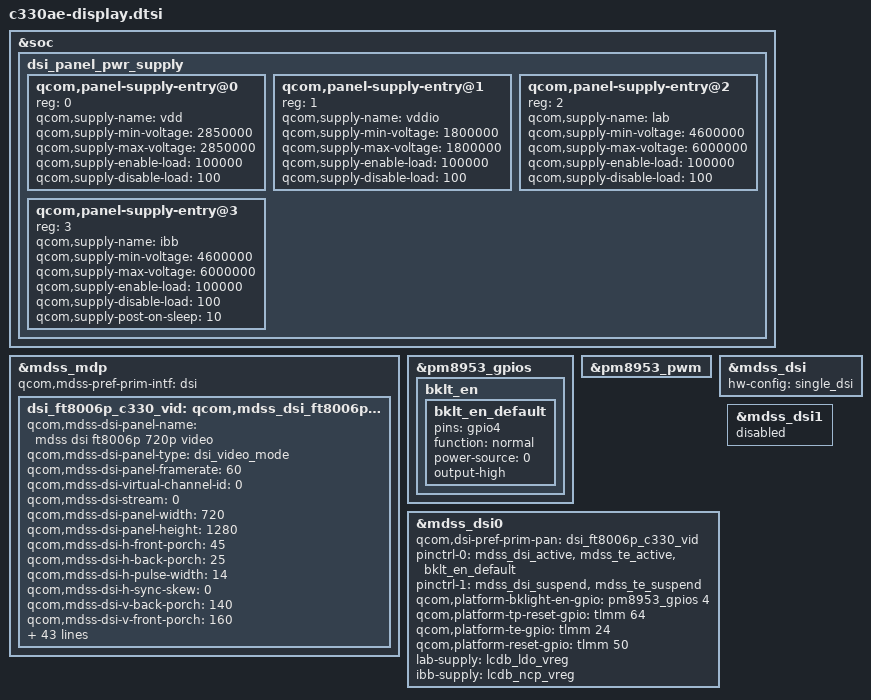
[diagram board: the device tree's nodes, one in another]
/* C330AE FT8006P 720p single-DSI panel. */

&soc {
	dsi_panel_pwr_supply: dsi_panel_pwr_supply {
		#address-cells = <1>;
		#size-cells = <0>;

		qcom,panel-supply-entry@0 {
			reg = <0>;
			qcom,supply-name = "vdd";
			qcom,supply-min-voltage = <2850000>;
			qcom,supply-max-voltage = <2850000>;
			qcom,supply-enable-load = <100000>;
			qcom,supply-disable-load = <100>;
		};

		qcom,panel-supply-entry@1 {
			reg = <1>;
			qcom,supply-name = "vddio";
			qcom,supply-min-voltage = <1800000>;
			qcom,supply-max-voltage = <1800000>;
			qcom,supply-enable-load = <100000>;
			qcom,supply-disable-load = <100>;
		};

		qcom,panel-supply-entry@2 {
			reg = <2>;
			qcom,supply-name = "lab";
			qcom,supply-min-voltage = <4600000>;
			qcom,supply-max-voltage = <6000000>;
			qcom,supply-enable-load = <100000>;
			qcom,supply-disable-load = <100>;
		};

		qcom,panel-supply-entry@3 {
			reg = <3>;
			qcom,supply-name = "ibb";
			qcom,supply-min-voltage = <4600000>;
			qcom,supply-max-voltage = <6000000>;
			qcom,supply-enable-load = <100000>;
			qcom,supply-disable-load = <100>;
			qcom,supply-post-on-sleep = <10>;
		};
	};
};

&mdss_mdp {
	qcom,mdss-pref-prim-intf = "dsi";

	dsi_ft8006p_c330_vid: qcom,mdss_dsi_ft8006p_720p_video {
		qcom,mdss-dsi-panel-name = "mdss dsi ft8006p 720p video";
		qcom,mdss-dsi-panel-type = "dsi_video_mode";
		qcom,mdss-dsi-panel-framerate = <60>;
		qcom,mdss-dsi-virtual-channel-id = <0>;
		qcom,mdss-dsi-stream = <0>;
		qcom,mdss-dsi-panel-width = <720>;
		qcom,mdss-dsi-panel-height = <1280>;
		qcom,mdss-dsi-h-front-porch = <45>;
		qcom,mdss-dsi-h-back-porch = <25>;
		qcom,mdss-dsi-h-pulse-width = <14>;
		qcom,mdss-dsi-h-sync-skew = <0>;
		qcom,mdss-dsi-v-back-porch = <140>;
		qcom,mdss-dsi-v-front-porch = <160>;
		qcom,mdss-dsi-v-pulse-width = <8>;
		qcom,mdss-dsi-h-left-border = <0>;
		qcom,mdss-dsi-h-right-border = <0>;
		qcom,mdss-dsi-v-top-border = <0>;
		qcom,mdss-dsi-v-bottom-border = <0>;
		qcom,mdss-pan-physical-width-dimension = <45>;
		qcom,mdss-pan-physical-height-dimension = <80>;
		qcom,mdss-dsi-bpp = <24>;
		qcom,mdss-dsi-color-order = "rgb_swap_rgb";
		qcom,mdss-dsi-underflow-color = <0xff>;
		qcom,mdss-dsi-border-color = <0>;
		qcom,mdss-dsi-on-command = [
			05 01 00 00 96 00 02 11 00
			05 01 00 00 14 00 02 29 00
		];
		qcom,mdss-dsi-off-command = [
			05 01 00 00 32 00 02 28 00
			05 01 00 00 96 00 02 10 00
			39 01 00 00 00 00 02 04 5A
			39 01 00 00 00 00 02 05 5A
		];
		qcom,mdss-dsi-on-command-state = "dsi_lp_mode";
		qcom,mdss-dsi-off-command-state = "dsi_lp_mode";
		qcom,mdss-dsi-panel-timings-phy-12nm = [08 06 09 02 00 04 02 08];
		qcom,mdss-dsi-h-sync-pulse = <0>;
		qcom,mdss-dsi-traffic-mode = "non_burst_sync_event";
		qcom,mdss-dsi-lane-map = "lane_map_0123";
		qcom,mdss-dsi-bllp-eof-power-mode;
		qcom,mdss-dsi-bllp-power-mode;
		qcom,mdss-dsi-tx-eot-append;
		qcom,mdss-dsi-lane-0-state;
		qcom,mdss-dsi-lane-1-state;
		qcom,mdss-dsi-lane-2-state;
		qcom,mdss-dsi-lane-3-state;
		qcom,mdss-dsi-t-clk-post = <4>;
		qcom,mdss-dsi-t-clk-pre = <0x1b>;
		qcom,mdss-dsi-dma-trigger = "trigger_sw";
		qcom,mdss-dsi-mdp-trigger = "none";
		qcom,mdss-dsi-lp11-init;
		qcom,mdss-dsi-reset-sequence = <1 20>, <0 20>, <1 50>;
		qcom,panel-supply-entries = <&dsi_panel_pwr_supply>;
		qcom,mdss-dsi-bl-pmic-control-type = "bl_ctrl_pwm";
		qcom,mdss-dsi-bl-pmic-pwm-frequency = <100>;
		qcom,mdss-dsi-bl-pmic-bank-select = <0>;
		qcom,mdss-dsi-pwm-gpio = <&pm8953_gpios 8 0>;
	};
};

&pm8953_gpios {
	bklt_en {
		bklt_en_default: bklt_en_default {
			pins = "gpio4";
			function = "normal";
			power-source = <0>;
			output-high;
		};
	};
};

&pm8953_pwm {
	status = "ok";
};

&mdss_dsi {
	hw-config = "single_dsi";
};

&mdss_dsi0 {
	qcom,dsi-pref-prim-pan = <&dsi_ft8006p_c330_vid>;
	pinctrl-names = "mdss_default", "mdss_sleep";
	pinctrl-0 = <&mdss_dsi_active &mdss_te_active &bklt_en_default>;
	pinctrl-1 = <&mdss_dsi_suspend &mdss_te_suspend>;
	qcom,platform-bklight-en-gpio = <&pm8953_gpios 4 0>;
	qcom,platform-tp-reset-gpio = <&tlmm 64 0>;
	qcom,platform-te-gpio = <&tlmm 24 0>;
	qcom,platform-reset-gpio = <&tlmm 50 0>;
	lab-supply = <&lcdb_ldo_vreg>;
	ibb-supply = <&lcdb_ncp_vreg>;
};

&mdss_dsi1 {
	status = "disabled";
};
